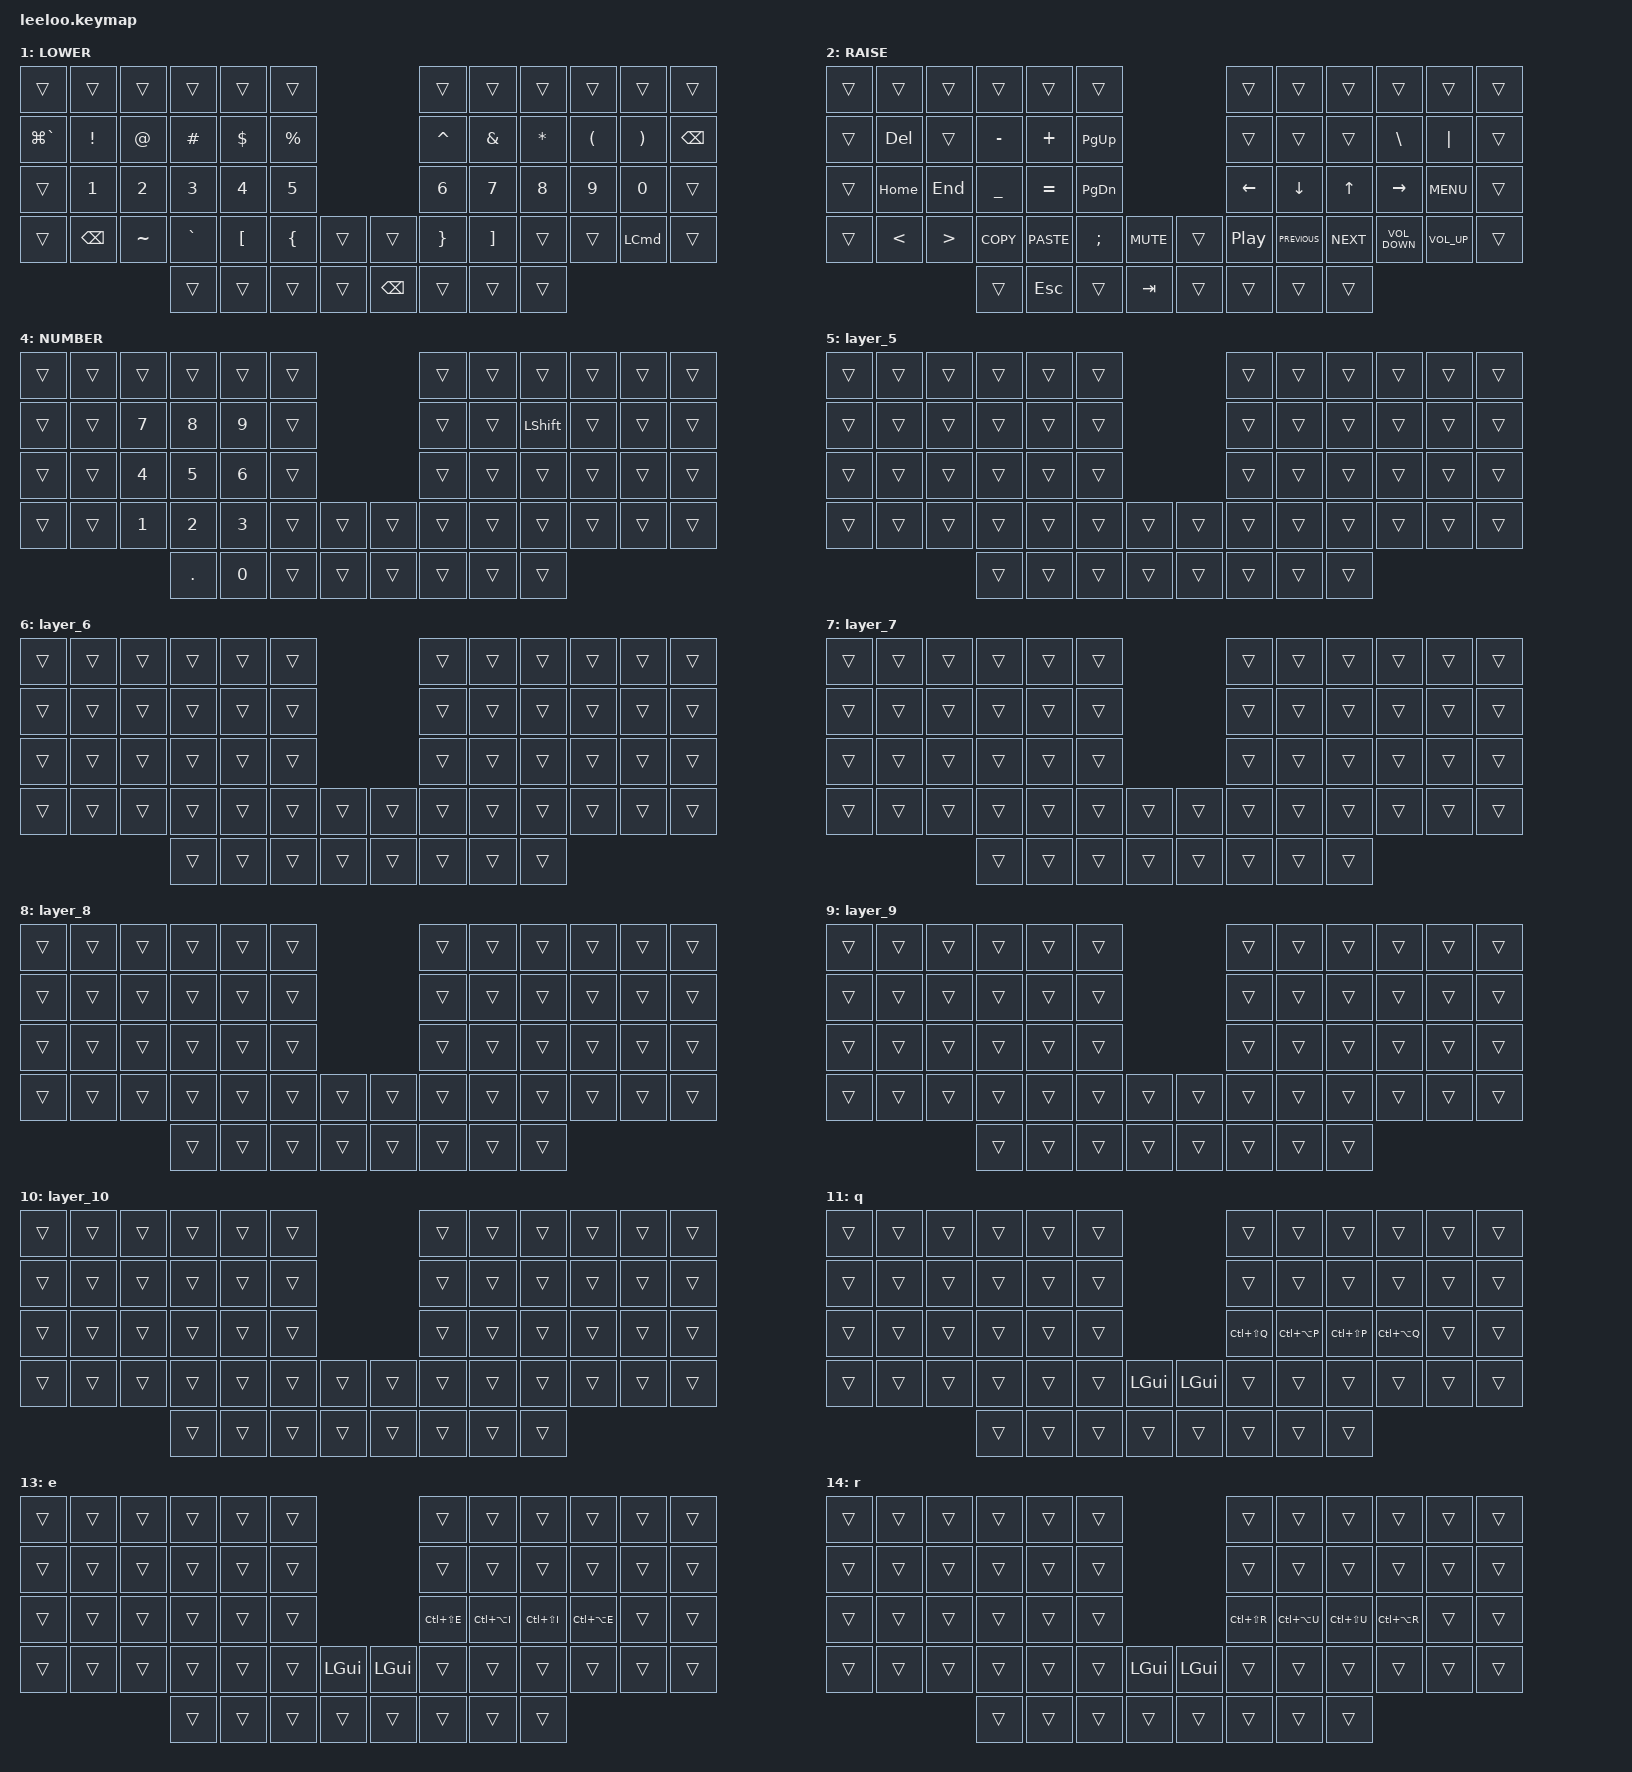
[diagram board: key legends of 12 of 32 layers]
/*
 * Copyright (c) 2023 The ZMK Contributors
 *
 * SPDX-License-Identifier: MIT
 */

#include <behaviors.dtsi>
#include <dt-bindings/zmk/bt.h>
#include <dt-bindings/zmk/keys.h>
#include <dt-bindings/zmk/rgb.h>

/*
  * Assign the cs-gpios pin to 4.
  * Uncomment these next few lines if implementing nice!view Displays
  */

nice_view_spi: &spi0 { cs-gpios = <&pro_micro 4 GPIO_ACTIVE_HIGH>; };

/ {
    combos {
        compatible = "zmk,combos";

        hyper_tab {
            bindings = <&lt 4 LS(LA(LC(LG(TAB))))>;
            key-positions = <53 54>;
        };

        command_space {
            bindings = <&kp LG(SPACE)>;
            key-positions = <52 55>;
        };

        esc {
            bindings = <&kp ESCAPE>;
            key-positions = <39 40>;
        };

        meh_tab {
            bindings = <&kp LC(LA(LS(TAB)))>;
            key-positions = <51 56>;
        };

        gui_right {
            bindings = <&sk LEFT_GUI>;
            key-positions = <31 32>;
        };

        shift_right {
            bindings = <&sk LEFT_SHIFT>;
            key-positions = <32 33>;
        };

        control_right {
            bindings = <&sk LEFT_CONTROL>;
            key-positions = <33 34>;
        };

        alt_right {
            bindings = <&sk LEFT_ALT>;
            key-positions = <31 33>;
        };

        meh_right {
            bindings = <&sk LA(LS(LEFT_CONTROL))>;
            key-positions = <34 32>;
        };

        hyper_right {
            bindings = <&sk LC(LA(LS(LEFT_COMMAND)))>;
            key-positions = <34 31>;
        };

        hyper_left {
            bindings = <&sk LC(LA(LS(LEFT_COMMAND)))>;
            key-positions = <28 25>;
        };

        meh_left {
            bindings = <&sk LA(LS(LEFT_CONTROL))>;
            key-positions = <25 27>;
        };

        alt_left {
            bindings = <&sk LEFT_ALT>;
            key-positions = <28 26>;
        };

        control_left {
            bindings = <&sk LEFT_CONTROL>;
            key-positions = <25 26>;
        };

        shift_left {
            bindings = <&sk LEFT_SHIFT>;
            key-positions = <27 26>;
        };

        gui_left {
            bindings = <&sk LEFT_GUI>;
            key-positions = <27 28>;
        };
    };

    keymap {
        compatible = "zmk,keymap";

        default_layer {
            display-name = " OSX";
            bindings = <
&kp GRAVE  &lt 26 N1  &lt 27 N2  &lt 28 N3                 &lt 29 N4               &lt 30 N5                                      &kp NUMBER_6  &kp N7                    &kp N8                    &kp N9      &kp N0     &tog 31
&kp TAB    &lt 11 Q   &lt 12 W   &lt 13 E                  &lt 14 R                &lt 15 T                                       &kp Y         &kp U                     &kp I                     &kp O       &kp P      &caps_word
&sk LALT   &lt 16 A   &lt 17 S   &lt 18 D                  &lt 19 F                &lt 20 G                                       &kp H         &kp J                     &kp K                     &kp L       &kp SQT    &kp SEMICOLON
&sk LSHFT  &lt 21 Z   &lt 22 X   &lt 23 C                  &lt 24 V                &lt 25 B             &lt 1 SPACE  &lt 4 ENTER  &kp N         &kp M                     &kp COMMA                 &kp PERIOD  &kp SLASH  &lt 3 EXCLAMATION
                                 &kp LS(LA(LC(LEFT_GUI)))  &mt LEFT_CONTROL SPACE  &mt LEFT_GUI RETURN  &lt 1 TAB    &lt 2 ESC    &kp SPACE     &mt LEFT_SHIFT BACKSPACE  &kp LS(LA(LEFT_CONTROL))
            >;

            sensor-bindings =
                <&inc_dec_kp LEFT RIGHT>,
                <&inc_dec_kp UP_ARROW DOWN_ARROW>;
        };

        lower_layer {
            display-name = "LOWER";
            bindings = <
&trans         &trans           &trans        &trans        &trans            &trans                                 &trans           &trans             &trans        &trans                &trans                 &trans
&kp LG(GRAVE)  &kp EXCLAMATION  &kp AT_SIGN   &kp HASH      &kp DOLLAR        &kp PERCENT                            &kp CARET        &kp AMPERSAND      &kp ASTERISK  &kp LEFT_PARENTHESIS  &kp RIGHT_PARENTHESIS  &kp BACKSPACE
&trans         &kp NUMBER_1     &kp NUMBER_2  &kp NUMBER_3  &kp NUMBER_4      &kp N5                                 &kp NUMBER_6     &kp N7             &kp N8        &kp N9                &kp N0                 &trans
&trans         &kp BACKSPACE    &kp TILDE     &kp GRAVE     &kp LEFT_BRACKET  &kp LEFT_BRACE  &trans  &trans         &kp RIGHT_BRACE  &kp RIGHT_BRACKET  &trans        &trans                &kp LEFT_COMMAND       &trans
                                              &trans        &trans            &trans          &trans  &kp BACKSPACE  &trans           &trans             &trans
            >;

            sensor-bindings =
                <&inc_dec_kp C_VOL_DN C_VOLUME_UP>,
                <&inc_dec_kp LEFT RIGHT>;
        };

        raise_layer {
            display-name = "RAISE";
            bindings = <
&trans  &trans         &trans            &trans      &trans       &trans                             &trans            &trans          &trans        &trans             &trans           &trans
&trans  &kp DELETE     &trans            &kp MINUS   &kp PLUS     &kp PAGE_UP                        &trans            &trans          &trans        &kp BACKSLASH      &kp PIPE         &trans
&trans  &kp HOME       &kp END           &kp UNDER   &kp EQUAL    &kp PAGE_DOWN                      &kp LEFT_ARROW    &kp DOWN_ARROW  &kp UP_ARROW  &kp RIGHT_ARROW    &kp K_MENU       &trans
&trans  &kp LESS_THAN  &kp GREATER_THAN  &kp K_COPY  &kp K_PASTE  &kp SEMICOLON  &kp K_MUTE  &trans  &kp C_PLAY_PAUSE  &kp C_PREVIOUS  &kp C_NEXT    &kp C_VOLUME_DOWN  &kp C_VOLUME_UP  &trans
                                         &trans      &kp ESCAPE   &trans         &kp TAB     &trans  &trans            &trans          &trans
            >;

            sensor-bindings =
                <&inc_dec_kp LS(TAB) TAB>,
                <&inc_dec_kp UP_ARROW DOWN_ARROW>;
        };

        function_layer {
            display-name = "FUNCTION";
            bindings = <
&trans                    &trans    &trans           &trans           &sys_reset       &bootloader                                       &bootloader   &sys_reset    &trans         &trans  &trans      &trans
&trans                    &kp F1    &kp F2           &kp F3           &kp F4           &kp F5                                            &kp F6        &kp F7        &kp F8         &kp F9  &kp F10     &trans
&trans                    &kp F11   &kp F12          &rgb_ug RGB_TOG  &rgb_ug RGB_BRD  &rgb_ug RGB_BRI                                   &bt BT_SEL 0  &bt BT_SEL 1  &bt BT_SEL 2   &trans  &bt BT_CLR  &trans
&kp LS(LG(LC(NUMBER_4)))  &kp CAPS  &rgb_ug RGB_SAD  &rgb_ug RGB_SAI  &rgb_ug RGB_HUD  &rgb_ug RGB_HUI  &kp C_PLAY_PAUSE  &trans         &trans        &trans        &bt BT_DISC 2  &trans  &trans      &kp PRINTSCREEN
                                                     &trans           &trans           &trans           &kp TAB           &kp BACKSPACE  &trans        &caps_word    &trans
            >;

            sensor-bindings =
                <&inc_dec_kp C_BRIGHTNESS_DEC C_BRI_UP>,
                <&inc_dec_kp UP_ARROW DOWN_ARROW>;
        };

        Number {
            display-name = "NUMBER";
            bindings = <
&trans  &trans  &trans        &trans        &trans        &trans                  &trans  &trans  &trans          &trans  &trans  &trans
&trans  &trans  &kp NUMBER_7  &kp N8        &kp N9        &trans                  &trans  &trans  &kp LEFT_SHIFT  &trans  &trans  &trans
&trans  &trans  &kp NUMBER_4  &kp NUMBER_5  &kp NUMBER_6  &trans                  &trans  &trans  &trans          &trans  &trans  &trans
&trans  &trans  &kp NUMBER_1  &kp NUMBER_2  &kp NUMBER_3  &trans  &trans  &trans  &trans  &trans  &trans          &trans  &trans  &trans
                              &kp PERIOD    &kp N0        &trans  &trans  &trans  &trans  &trans  &trans
            >;

            sensor-bindings =
                <&inc_dec_kp LC(LA(LS(LG(LEFT)))) LA(LC(LS(LG(RIGHT))))>,
                <&inc_dec_kp LS(LA(LC(UP_ARROW))) LS(LC(LA(DOWN)))>;
        };

        layer_5 {
            bindings = <
&trans  &trans  &trans  &trans  &trans  &trans                  &trans  &trans  &trans  &trans  &trans  &trans
&trans  &trans  &trans  &trans  &trans  &trans                  &trans  &trans  &trans  &trans  &trans  &trans
&trans  &trans  &trans  &trans  &trans  &trans                  &trans  &trans  &trans  &trans  &trans  &trans
&trans  &trans  &trans  &trans  &trans  &trans  &trans  &trans  &trans  &trans  &trans  &trans  &trans  &trans
                        &trans  &trans  &trans  &trans  &trans  &trans  &trans  &trans
            >;

            sensor-bindings = <&inc_dec_kp 0 0>, <&inc_dec_kp 0 0>;
        };

        layer_6 {
            bindings = <
&trans  &trans  &trans  &trans  &trans  &trans                  &trans  &trans  &trans  &trans  &trans  &trans
&trans  &trans  &trans  &trans  &trans  &trans                  &trans  &trans  &trans  &trans  &trans  &trans
&trans  &trans  &trans  &trans  &trans  &trans                  &trans  &trans  &trans  &trans  &trans  &trans
&trans  &trans  &trans  &trans  &trans  &trans  &trans  &trans  &trans  &trans  &trans  &trans  &trans  &trans
                        &trans  &trans  &trans  &trans  &trans  &trans  &trans  &trans
            >;
        };

        layer_7 {
            bindings = <
&trans  &trans  &trans  &trans  &trans  &trans                  &trans  &trans  &trans  &trans  &trans  &trans
&trans  &trans  &trans  &trans  &trans  &trans                  &trans  &trans  &trans  &trans  &trans  &trans
&trans  &trans  &trans  &trans  &trans  &trans                  &trans  &trans  &trans  &trans  &trans  &trans
&trans  &trans  &trans  &trans  &trans  &trans  &trans  &trans  &trans  &trans  &trans  &trans  &trans  &trans
                        &trans  &trans  &trans  &trans  &trans  &trans  &trans  &trans
            >;
        };

        layer_8 {
            bindings = <
&trans  &trans  &trans  &trans  &trans  &trans                  &trans  &trans  &trans  &trans  &trans  &trans
&trans  &trans  &trans  &trans  &trans  &trans                  &trans  &trans  &trans  &trans  &trans  &trans
&trans  &trans  &trans  &trans  &trans  &trans                  &trans  &trans  &trans  &trans  &trans  &trans
&trans  &trans  &trans  &trans  &trans  &trans  &trans  &trans  &trans  &trans  &trans  &trans  &trans  &trans
                        &trans  &trans  &trans  &trans  &trans  &trans  &trans  &trans
            >;
        };

        layer_9 {
            bindings = <
&trans  &trans  &trans  &trans  &trans  &trans                  &trans  &trans  &trans  &trans  &trans  &trans
&trans  &trans  &trans  &trans  &trans  &trans                  &trans  &trans  &trans  &trans  &trans  &trans
&trans  &trans  &trans  &trans  &trans  &trans                  &trans  &trans  &trans  &trans  &trans  &trans
&trans  &trans  &trans  &trans  &trans  &trans  &trans  &trans  &trans  &trans  &trans  &trans  &trans  &trans
                        &trans  &trans  &trans  &trans  &trans  &trans  &trans  &trans
            >;
        };

        layer_10 {
            bindings = <
&trans  &trans  &trans  &trans  &trans  &trans                  &trans  &trans  &trans  &trans  &trans  &trans
&trans  &trans  &trans  &trans  &trans  &trans                  &trans  &trans  &trans  &trans  &trans  &trans
&trans  &trans  &trans  &trans  &trans  &trans                  &trans  &trans  &trans  &trans  &trans  &trans
&trans  &trans  &trans  &trans  &trans  &trans  &trans  &trans  &trans  &trans  &trans  &trans  &trans  &trans
                        &trans  &trans  &trans  &trans  &trans  &trans  &trans  &trans
            >;

            sensor-bindings = <&inc_dec_kp 0 0>;
        };

        q {
            bindings = <
&trans  &trans  &trans  &trans  &trans  &trans                              &trans         &trans         &trans         &trans         &trans  &trans
&trans  &trans  &trans  &trans  &trans  &trans                              &trans         &trans         &trans         &trans         &trans  &trans
&trans  &trans  &trans  &trans  &trans  &trans                              &kp LC(LS(Q))  &kp LC(LA(P))  &kp LC(LS(P))  &kp LC(LA(Q))  &trans  &trans
&trans  &trans  &trans  &trans  &trans  &trans  &kp LEFT_GUI  &kp LEFT_GUI  &trans         &trans         &trans         &trans         &trans  &trans
                        &trans  &trans  &trans  &trans        &trans        &trans         &trans         &trans
            >;

            sensor-bindings =
                <&inc_dec_kp LS(LC(Q)) LC(LA(Q))>,
                <&inc_dec_kp LC(LS(P)) LC(LA(P))>;
        };

        w {
            bindings = <
&trans  &trans  &trans  &trans  &trans  &trans                              &trans         &trans         &trans         &trans         &trans  &trans
&trans  &trans  &trans  &trans  &trans  &trans                              &trans         &trans         &trans         &trans         &trans  &trans
&trans  &trans  &trans  &trans  &trans  &trans                              &kp LC(LS(W))  &kp LC(LA(O))  &kp LC(LS(O))  &kp LC(LA(W))  &trans  &trans
&trans  &trans  &trans  &trans  &trans  &trans  &kp LEFT_GUI  &kp LEFT_GUI  &trans         &trans         &trans         &trans         &trans  &trans
                        &trans  &trans  &trans  &trans        &trans        &trans         &trans
            >;

            sensor-bindings =
                <&inc_dec_kp LS(LC(W)) LC(LA(W))>,
                <&inc_dec_kp LC(LS(O)) LC(LA(O))>;
        };

        e {
            bindings = <
&trans  &trans  &trans  &trans  &trans  &trans                              &trans         &trans         &trans         &trans         &trans  &trans
&trans  &trans  &trans  &trans  &trans  &trans                              &trans         &trans         &trans         &trans         &trans  &trans
&trans  &trans  &trans  &trans  &trans  &trans                              &kp LC(LS(E))  &kp LC(LA(I))  &kp LC(LS(I))  &kp LC(LA(E))  &trans  &trans
&trans  &trans  &trans  &trans  &trans  &trans  &kp LEFT_GUI  &kp LEFT_GUI  &trans         &trans         &trans         &trans         &trans  &trans
                        &trans  &trans  &trans  &trans        &trans        &trans         &trans         &trans
            >;

            sensor-bindings =
                <&inc_dec_kp LS(LC(E)) LC(LA(E))>,
                <&inc_dec_kp LC(LS(I)) LC(LA(I))>;
        };

        r {
            bindings = <
&trans  &trans  &trans  &trans  &trans  &trans                              &trans         &trans         &trans         &trans         &trans  &trans
&trans  &trans  &trans  &trans  &trans  &trans                              &trans         &trans         &trans         &trans         &trans  &trans
&trans  &trans  &trans  &trans  &trans  &trans                              &kp LC(LS(R))  &kp LC(LA(U))  &kp LC(LS(U))  &kp LC(LA(R))  &trans  &trans
&trans  &trans  &trans  &trans  &trans  &trans  &kp LEFT_GUI  &kp LEFT_GUI  &trans         &trans         &trans         &trans         &trans  &trans
                        &trans  &trans  &trans  &trans        &trans        &trans         &trans         &trans
            >;

            sensor-bindings =
                <&inc_dec_kp LS(LC(R)) LC(LA(R))>,
                <&inc_dec_kp LC(LS(U)) LC(LA(U))>;
        };

        t {
            bindings = <
&trans  &trans  &trans  &trans  &trans  &trans                              &trans         &trans         &trans         &trans         &trans  &trans
&trans  &trans  &trans  &trans  &trans  &trans                              &trans         &trans         &trans         &trans         &trans  &trans
&trans  &trans  &trans  &trans  &trans  &trans                              &kp LC(LS(T))  &kp LC(LA(Y))  &kp LC(LS(Y))  &kp LC(LA(T))  &trans  &trans
&trans  &trans  &trans  &trans  &trans  &trans  &kp LEFT_GUI  &kp LEFT_GUI  &trans         &trans         &trans         &trans         &trans  &trans
                        &trans  &trans  &trans  &trans        &trans        &trans         &trans         &trans
            >;

            sensor-bindings =
                <&inc_dec_kp LS(LC(T)) LC(LA(T))>,
                <&inc_dec_kp LC(LS(Y)) LC(LA(Y))>;
        };

        a {
            bindings = <
&trans  &trans  &trans  &trans  &trans  &trans                              &trans         &trans           &trans           &trans         &trans  &trans
&trans  &trans  &trans  &trans  &trans  &trans                              &trans         &trans           &trans           &trans         &trans  &trans
&trans  &trans  &trans  &trans  &trans  &trans                              &kp LC(LS(A))  &kp LC(LA(SQT))  &kp LC(LS(SQT))  &kp LC(LA(A))  &trans  &trans
&trans  &trans  &trans  &trans  &trans  &trans  &kp LEFT_GUI  &kp LEFT_GUI  &trans         &trans           &trans           &trans         &trans  &trans
                        &trans  &trans  &trans  &trans        &trans        &trans         &trans           &trans
            >;

            sensor-bindings =
                <&inc_dec_kp LS(LC(A)) LC(LA(A))>,
                <&inc_dec_kp LC(LS(SQT)) LC(LA(SQT))>;
        };

        s {
            bindings = <
&trans  &trans  &trans  &trans  &trans  &trans                              &trans         &trans         &trans         &trans         &trans  &trans
&trans  &trans  &trans  &trans  &trans  &trans                              &trans         &trans         &trans         &trans         &trans  &trans
&trans  &trans  &trans  &trans  &trans  &trans                              &kp LC(LS(S))  &kp LC(LA(L))  &kp LC(LS(L))  &kp LC(LA(S))  &trans  &trans
&trans  &trans  &trans  &trans  &trans  &trans  &kp LEFT_GUI  &kp LEFT_GUI  &trans         &trans         &trans         &trans         &trans  &trans
                        &trans  &trans  &trans  &trans        &trans        &trans         &trans         &trans
            >;

            sensor-bindings =
                <&inc_dec_kp LS(LC(S)) LC(LA(S))>,
                <&inc_dec_kp LC(LS(L)) LC(LA(L))>;
        };

        d {
            bindings = <
&trans  &trans  &trans  &trans  &trans  &trans                              &trans         &trans         &trans         &trans         &trans  &trans
&trans  &trans  &trans  &trans  &trans  &trans                              &trans         &trans         &trans         &trans         &trans  &trans
&trans  &trans  &trans  &trans  &trans  &trans                              &kp LC(LS(D))  &kp LC(LA(K))  &kp LC(LS(K))  &kp LC(LA(D))  &trans  &trans
&trans  &trans  &trans  &trans  &trans  &trans  &kp LEFT_GUI  &kp LEFT_GUI  &trans         &trans         &trans         &trans         &trans  &trans
                        &trans  &trans  &trans  &trans        &trans        &trans         &trans         &trans
            >;

            sensor-bindings =
                <&inc_dec_kp LS(LC(D)) LC(LA(D))>,
                <&inc_dec_kp LC(LS(K)) LC(LA(K))>;
        };

        f {
            bindings = <
&trans  &trans  &trans  &trans  &trans  &trans                              &trans         &trans         &trans         &trans         &trans  &trans
&trans  &trans  &trans  &trans  &trans  &trans                              &trans         &trans         &trans         &trans         &trans  &trans
&trans  &trans  &trans  &trans  &trans  &trans                              &kp LC(LS(F))  &kp LC(LA(J))  &kp LC(LS(J))  &kp LC(LA(F))  &trans  &trans
&trans  &trans  &trans  &trans  &trans  &trans  &kp LEFT_GUI  &kp LEFT_GUI  &trans         &trans         &trans         &trans         &trans  &trans
                        &trans  &trans  &trans  &trans        &trans        &trans         &trans         &trans
            >;

            sensor-bindings =
                <&inc_dec_kp LS(LC(F)) LC(LA(F))>,
                <&inc_dec_kp LC(LS(J)) LC(LA(J))>;
        };

        g {
            bindings = <
&trans  &trans  &trans  &trans  &trans  &trans                              &trans         &trans         &trans         &trans         &trans  &trans
&trans  &trans  &trans  &trans  &trans  &trans                              &trans         &trans         &trans         &trans         &trans  &trans
&trans  &trans  &trans  &trans  &trans  &trans                              &kp LC(LS(G))  &kp LC(LA(H))  &kp LC(LS(H))  &kp LC(LA(G))  &trans  &trans
&trans  &trans  &trans  &trans  &trans  &trans  &kp LEFT_GUI  &kp LEFT_GUI  &trans         &trans         &trans         &trans         &trans  &trans
                        &trans  &trans  &trans  &trans        &trans        &trans         &trans         &trans
            >;

            sensor-bindings =
                <&inc_dec_kp LS(LC(G)) LC(LA(G))>,
                <&inc_dec_kp LC(LS(H)) LC(LA(H))>;
        };

        z {
            bindings = <
&trans  &trans  &trans  &trans  &trans  &trans                              &trans         &trans             &trans             &trans         &trans  &trans
&trans  &trans  &trans  &trans  &trans  &trans                              &trans         &trans             &trans             &trans         &trans  &trans
&trans  &trans  &trans  &trans  &trans  &trans                              &kp LC(LS(Z))  &kp LC(LA(SLASH))  &kp LC(LS(SLASH))  &kp LC(LA(Z))  &trans  &trans
&trans  &trans  &trans  &trans  &trans  &trans  &kp LEFT_GUI  &kp LEFT_GUI  &trans         &trans             &trans             &trans         &trans  &trans
                        &trans  &trans  &trans  &trans        &trans        &trans         &trans             &trans
            >;

            sensor-bindings =
                <&inc_dec_kp LS(LC(Z)) LC(LA(Z))>,
                <&inc_dec_kp LC(LS(SLASH)) LC(LA(SLASH))>;
        };

        x {
            bindings = <
&trans  &trans  &trans  &trans  &trans  &trans                              &trans         &trans              &trans              &trans         &trans  &trans
&trans  &trans  &trans  &trans  &trans  &trans                              &trans         &trans              &trans              &trans         &trans  &trans
&trans  &trans  &trans  &trans  &trans  &trans                              &kp LC(LS(X))  &kp LC(LA(PERIOD))  &kp LC(LS(PERIOD))  &kp LC(LA(X))  &trans  &trans
&trans  &trans  &trans  &trans  &trans  &trans  &kp LEFT_GUI  &kp LEFT_GUI  &trans         &trans              &trans              &trans         &trans  &trans
                        &trans  &trans  &trans  &trans        &trans        &trans         &trans              &trans
            >;

            sensor-bindings =
                <&inc_dec_kp LC(LS(X)) LC(LA(X))>,
                <&inc_dec_kp LC(LS(PERIOD)) LC(LA(PERIOD))>;
        };

        c {
            bindings = <
&trans  &trans  &trans  &trans  &trans  &trans                              &trans         &trans             &trans             &trans         &trans  &trans
&trans  &trans  &trans  &trans  &trans  &trans                              &trans         &trans             &trans             &trans         &trans  &trans
&trans  &trans  &trans  &trans  &trans  &trans                              &kp LC(LS(C))  &kp LC(LA(COMMA))  &kp LC(LS(COMMA))  &kp LC(LA(C))  &trans  &trans
&trans  &trans  &trans  &trans  &trans  &trans  &kp LEFT_GUI  &kp LEFT_GUI  &trans         &trans             &trans             &trans         &trans  &trans
                        &trans  &trans  &trans  &trans        &trans        &trans         &trans             &trans
            >;

            sensor-bindings =
                <&inc_dec_kp LC(LS(C)) LC(LA(C))>,
                <&inc_dec_kp LC(LS(COMMA)) LC(LA(COMMA))>;
        };

        v {
            bindings = <
&trans  &trans  &trans  &trans  &trans  &trans                              &trans         &trans         &trans         &trans         &trans  &trans
&trans  &trans  &trans  &trans  &trans  &trans                              &trans         &trans         &trans         &trans         &trans  &trans
&trans  &trans  &trans  &trans  &trans  &trans                              &kp LC(LS(V))  &kp LC(LA(M))  &kp LC(LS(M))  &kp LC(LA(V))  &trans  &trans
&trans  &trans  &trans  &trans  &trans  &trans  &kp LEFT_GUI  &kp LEFT_GUI  &trans         &trans         &trans         &trans         &trans  &trans
                        &trans  &trans  &trans  &trans        &trans        &trans         &trans         &trans
            >;

            sensor-bindings =
                <&inc_dec_kp LC(LS(V)) LC(LA(V))>,
                <&inc_dec_kp LC(LS(M)) LC(LA(M))>;
        };

        b {
            bindings = <
&trans  &trans  &trans  &trans  &trans  &trans                              &trans         &trans         &trans         &trans         &trans  &trans
&trans  &trans  &trans  &trans  &trans  &trans                              &trans         &trans         &trans         &trans         &trans  &trans
&trans  &trans  &trans  &trans  &trans  &trans                              &kp LC(LS(B))  &kp LC(LA(N))  &kp LC(LS(N))  &kp LC(LA(B))  &trans  &trans
&trans  &trans  &trans  &trans  &trans  &trans  &kp LEFT_GUI  &kp LEFT_GUI  &trans         &trans         &trans         &trans         &trans  &trans
                        &trans  &trans  &trans  &trans        &trans        &trans         &trans         &trans
            >;

            sensor-bindings =
                <&inc_dec_kp LC(LS(B)) LC(LA(B))>,
                <&inc_dec_kp LC(LS(N)) LC(LA(N))>;
        };

        n1 {
            bindings = <
&trans  &trans  &trans  &trans  &trans  &trans                              &trans                &trans          &trans          &trans                &trans  &trans
&trans  &trans  &trans  &trans  &trans  &trans                              &trans                &trans          &trans          &trans                &trans  &trans
&trans  &trans  &trans  &trans  &trans  &trans                              &kp LC(LS(NUMBER_1))  &kp LC(LA(N0))  &kp LC(LS(N0))  &kp LC(LA(NUMBER_1))  &trans  &trans
&trans  &trans  &trans  &trans  &trans  &trans  &kp LEFT_GUI  &kp LEFT_GUI  &trans                &trans          &trans          &trans                &trans  &trans
                        &trans  &trans  &trans  &trans        &trans        &trans                &trans          &trans
            >;

            sensor-bindings =
                <&inc_dec_kp LC(LS(NUMBER_1)) LC(LA(NUMBER_1))>,
                <&inc_dec_kp LC(LS(N0)) LC(LA(N0))>;
        };

        n2 {
            bindings = <
&trans  &trans  &trans  &trans  &trans  &trans                              &trans                &trans          &trans          &trans                &trans  &trans
&trans  &trans  &trans  &trans  &trans  &trans                              &trans                &trans          &trans          &trans                &trans  &trans
&trans  &trans  &trans  &trans  &trans  &trans                              &kp LC(LS(NUMBER_2))  &kp LC(LA(N9))  &kp LC(LS(N9))  &kp LC(LA(NUMBER_2))  &trans  &trans
&trans  &trans  &trans  &trans  &trans  &trans  &kp LEFT_GUI  &kp LEFT_GUI  &trans                &trans          &trans          &trans                &trans  &trans
                        &trans  &trans  &trans  &trans        &trans        &trans                &trans          &trans
            >;

            sensor-bindings =
                <&inc_dec_kp LC(LS(NUMBER_2)) LC(LA(NUMBER_2))>,
                <&inc_dec_kp LC(LS(N9)) LC(LA(N9))>;
        };

        n3 {
            bindings = <
&trans  &trans  &trans  &trans  &trans  &trans                              &trans                &trans          &trans          &trans                &trans  &trans
&trans  &trans  &trans  &trans  &trans  &trans                              &trans                &trans          &trans          &trans                &trans  &trans
&trans  &trans  &trans  &trans  &trans  &trans                              &kp LC(LS(NUMBER_3))  &kp LC(LA(N8))  &kp LC(LS(N8))  &kp LC(LA(NUMBER_3))  &trans  &trans
&trans  &trans  &trans  &trans  &trans  &trans  &kp LEFT_GUI  &kp LEFT_GUI  &trans                &trans          &trans          &trans                &trans  &trans
                        &trans  &trans  &trans  &trans        &trans        &trans                &trans          &trans
            >;

            sensor-bindings =
                <&inc_dec_kp LC(LS(NUMBER_3)) LC(LA(NUMBER_3))>,
                <&inc_dec_kp LC(LS(N8)) LC(LA(N8))>;
        };

        n4 {
            bindings = <
&trans  &trans  &trans  &trans  &trans  &trans                              &trans                &trans          &trans          &trans                &trans  &trans
&trans  &trans  &trans  &trans  &trans  &trans                              &trans                &trans          &trans          &trans                &trans  &trans
&trans  &trans  &trans  &trans  &trans  &trans                              &kp LC(LS(NUMBER_4))  &kp LC(LA(N7))  &kp LC(LS(N7))  &kp LC(LA(NUMBER_4))  &trans  &trans
&trans  &trans  &trans  &trans  &trans  &trans  &kp LEFT_GUI  &kp LEFT_GUI  &trans                &trans          &trans          &trans                &trans  &trans
                        &trans  &trans  &trans  &trans        &trans        &trans                &trans          &trans
            >;

            sensor-bindings =
                <&inc_dec_kp LC(LS(NUMBER_4)) LC(LA(NUMBER_4))>,
                <&inc_dec_kp LC(LS(N7)) LC(LA(N7))>;
        };

        n5 {
            bindings = <
&trans  &trans  &trans  &trans  &trans  &trans                              &trans          &trans                &trans                &trans          &trans  &trans
&trans  &trans  &trans  &trans  &trans  &trans                              &trans          &trans                &trans                &trans          &trans  &trans
&trans  &trans  &trans  &trans  &trans  &trans                              &kp LC(LS(N5))  &kp LC(LA(NUMBER_6))  &kp LC(LS(NUMBER_6))  &kp LC(LA(N5))  &trans  &trans
&trans  &trans  &trans  &trans  &trans  &trans  &kp LEFT_GUI  &kp LEFT_GUI  &trans          &trans                &trans                &trans          &trans  &trans
                        &trans  &trans  &trans  &trans        &trans        &trans          &trans                &trans
            >;

            sensor-bindings =
                <&inc_dec_kp LC(LS(N5)) LC(LA(N5))>,
                <&inc_dec_kp LC(LS(NUMBER_6)) LC(LA(NUMBER_6))>;
        };

        kp_only {
            bindings = <
&kp GRAVE  &kp N1  &kp N2  &kp N3                 &kp N4     &kp N5                       &kp N6     &kp N7    &kp N8     &kp N9   &kp N0    &trans
&kp TAB    &kp Q   &kp W   &kp E                  &kp R      &kp T                        &kp Y      &kp U     &kp I      &kp O    &kp P     &kp DEL
&kp LGUI   &kp A   &kp S   &kp D                  &kp F      &kp G                        &kp H      &kp J     &kp K      &kp L    &kp SQT   &kp SEMI
&kp LSHFT  &kp Z   &kp X   &kp C                  &kp V      &kp B    &kp SPACE  &kp RET  &kp N      &kp M     &kp COMMA  &kp DOT  &kp FSLH  &trans
                           &kp LS(LG(LA(LCTRL)))  &kp SPACE  &kp RET  &kp TAB    &kp ESC  &kp SPACE  &kp BSPC  &kp LALT
            >;
        };
    };

    conditional_layers {
        display-name = "NUMBER";
        compatible = "zmk,conditional-layers";
    };
};
